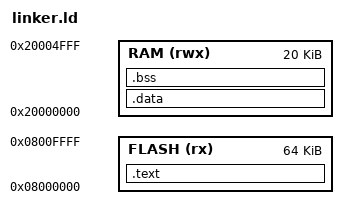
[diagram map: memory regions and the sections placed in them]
MEMORY
{
    FLASH (rx)  : ORIGIN = 0x08000000, LENGTH = 64K
    RAM   (rwx) : ORIGIN = 0x20000000, LENGTH = 20K
}

_estack = ORIGIN(RAM) + LENGTH(RAM);

SECTIONS
{
    .text :
    {
        . = ALIGN(4);

        KEEP(*(.isr_vector))

        *(.text*)
        *(.rodata*)

        . = ALIGN(4);

        _etext = .;
    } > FLASH

    _sidata = LOADADDR(.data);

    .data : AT (_etext)
    {
        . = ALIGN(4);

        _sdata = .;

        *(.data*)

        . = ALIGN(4);

        _edata = .;
    } > RAM

    .bss :
    {
        . = ALIGN(4);

        _sbss = .;

        *(.bss*)
        *(COMMON)

        . = ALIGN(4);

        _ebss = .;
    } > RAM
}
